# YT9215 register map
Vendor: Motorcomm; Series: YT921x; File version: 1.0
Registers are 32-bit, read-write, no defined reset value unless marked. A register's access mark holds for its fields unless they carry their own. Offsets are from the block's base; [hi:lo] are bit positions; lines under a group give offsets from that group; {n}, {i} and the like mark numbered series; 'fields as' and 'values as' point back to an identical list.

## EDATA — Configuration byte store and clock
Base 0x000E0000
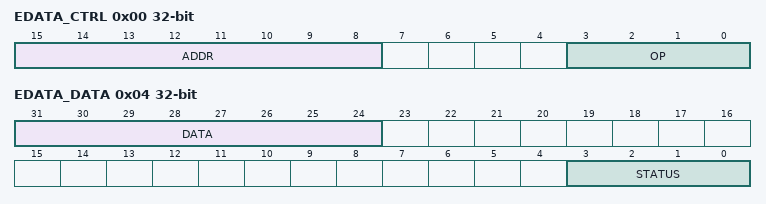
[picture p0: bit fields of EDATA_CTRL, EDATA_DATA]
0x00 EDATA_CTRL — Command register of the configuration byte store of 256 bytes. Writing it starts the command; Identify the part shows the read sequence.
  [15:8] ADDR — Byte address from 0 to 255.
  [3:0] OP — Command.
    5=READ (Read the byte at EDATA_CTRL.ADDR into EDATA_DATA.DATA)
0x04 EDATA_DATA ro — Result and state of the last EDATA_CTRL command.
  [31:24] DATA — Byte that was read.
  [3:0] STATUS — State of the store.
    3=IDLE (No command is running. EDATA_DATA.DATA is valid)
0x40 SYS_CLK — Shows which core clock the switch runs from. yt921x_chip_detect reads it. The time slots of METER_SLOT and PORT_SHAPE_SLOT count in units of eight core clock periods.
  [1:0] SEL — Core clock in use. Value 0 stands for 125 MHz in the YT9215 family and 167 MHz in the YT9218 family. The core clock table lists the clock periods.
    0=V125M (125 MHz core clock); 1=V143M (143 MHz core clock)

## INT_MBUS — Internal MDIO master
Base 0x000F0000
0x00 INT_MBUS_OP — Starts a transfer on the internal MDIO master and shows when it has finished; see MDIO master transfer.
  [0] START — Write 1 to start the transfer set up in INT_MBUS_CTRL. Reads 1 until the transfer is complete.
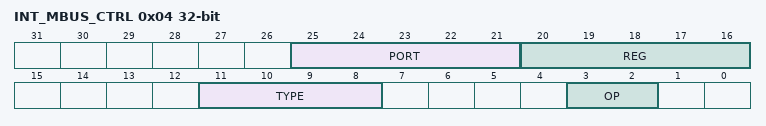
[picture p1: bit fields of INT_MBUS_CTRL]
0x04 INT_MBUS_CTRL — Address and direction of the next transfer to a built-in PHY or SerDes PCS.
  [25:21] PORT — PHY address from 0 to 31. On the internal bus it equals the port number.
  [20:16] REG — PHY register number from 0 to 31.
  [11:8] TYPE — Frame format. The comment on the field reads "wild guess", so the width of the field is inferred.
    4=C22 (IEEE 802.3 clause 22 frame)
  [3:2] OP — Direction. The comment on the field reads "wild guess", so the width of the field is inferred.
    1=WRITE (Write the register); 2=READ (Read the register)
0x08 INT_MBUS_DOUT — Data for the next write transfer on the internal MDIO master.
  [15:0] DATA — The 16-bit PHY register value.
0x0C INT_MBUS_DIN ro — Data returned by the last read transfer on the internal MDIO master.
  [15:0] DATA — The 16-bit PHY register value.

## EGRESS — Egress tag processing
Base 0x00100000
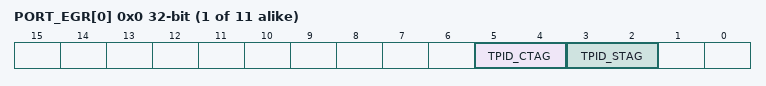
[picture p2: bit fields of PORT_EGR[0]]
{0x0+4i} PORT_EGR[{i}] (i=0..10) — Chooses which TPID_EGR entry a port writes into the VLAN tags it adds on transmit. Index: port = 0 to 10.
  [5:4] TPID_CTAG — Index of the TPID_EGR entry used for customer tags.
  [3:2] TPID_STAG — Index of the TPID_EGR entry used for service tags.
{0x300+4i} TPID_EGR[{i}] (i=0..3) — Four tag protocol identifier values a port can write into transmitted VLAN tags. Index: n = 0 to 3.
  [15:0] TPID — Tag protocol identifier. An example is 0x8100.

## ACL_ACTION — ACL action table
Base 0x001C0000
{0x0+0x10*i} ACL_ACT[{i}] (i=0..383) group — 96-bit action of one rule. The entry index is 8 × blk + the group number of the rule in ACL_ENTRY.GRPID. Write the three words in rising address order. Index: entry = 0 to 383.
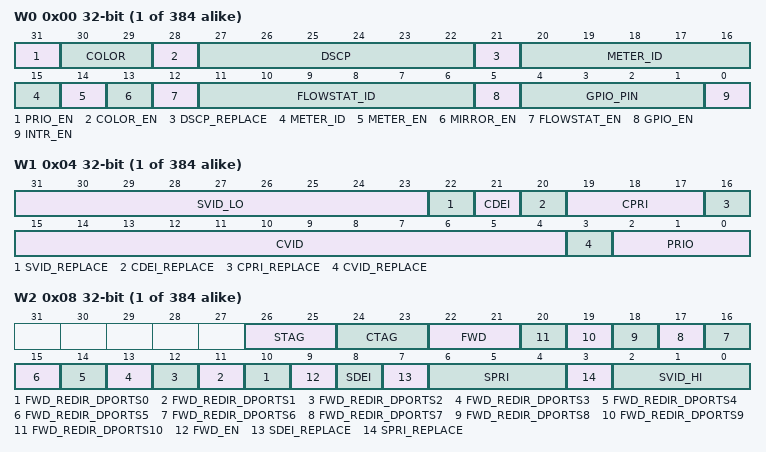
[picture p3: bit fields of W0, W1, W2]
  0x00 W0 — ACL action entry: bits 31 to 0. 96-bit action of one rule. The entry index is 8 × blk + the group number of the rule in ACL_ENTRY.GRPID. Write the three words in rising address order.
    [31] PRIO_EN — Enables ACL_ACT.PRIO.
    [30:29] COLOR — Colour given to the frame.
      0=GREEN; 1=YELLOW; 2=RED
    [28] COLOR_EN — Enables ACL_ACT.COLOR.
    [27:22] DSCP — New IP DSCP value.
    [21] DSCP_REPLACE — Replace the IP DSCP value.
    [20:15] METER_ID — Meter that rate limits matching frames. It is an index of METER_CTRL.
    [14] METER_EN — Enables ACL_ACT.METER_ID.
    [13] MIRROR_EN — Copy matching frames to the monitor port in MIRROR.PORT.
    [12] FLOWSTAT_EN — Count matching frames in the flow counter ACL_ACT.FLOWSTAT_ID.
    [11:6] FLOWSTAT_ID — Flow counter number.
    [5] GPIO_EN — Signal a match on the pin in ACL_ACT.GPIO_PIN.
    [4:1] GPIO_PIN — Pin number.
    [0] INTR_EN — Raise an interrupt on a match.
  0x04 W1 — ACL action entry: bits 63 to 32. 96-bit action of one rule. The entry index is 8 × blk + the group number of the rule in ACL_ENTRY.GRPID. Write the three words in rising address order.
    [31:23] SVID_LO — New service VLAN ID. The field crosses the boundary between words 1 and 2.
    [22] SVID_REPLACE — Replace the service VLAN ID.
    [21] CDEI — New drop eligible bit of the customer tag.
    [20] CDEI_REPLACE — Replace the drop eligible bit of the customer tag.
    [19:17] CPRI — New priority of the customer tag.
    [16] CPRI_REPLACE — Replace the priority of the customer tag.
    [15:4] CVID — New customer VLAN ID.
    [3] CVID_REPLACE — Replace the customer VLAN ID.
    [2:0] PRIO — Internal priority given to the frame. It is inferred that it is a source for PORT_PRIO_ORD.
  0x08 W2 — ACL action entry: bits 95 to 64. 96-bit action of one rule. The entry index is 8 × blk + the group number of the rule in ACL_ENTRY.GRPID. Write the three words in rising address order.
    [26:25] STAG — Service tag handling on transmit.
      0=DONTCARE (Leave to the normal VLAN rules); 1=UNTAG (Send without the tag); 2=TAG (Send with the tag); 3=KEEP (Send as received)
    [24:23] CTAG — Customer tag handling on transmit.
      values as STAG
    [22:21] FWD — Forwarding action. It is used when ACL_ACT.FWD_EN is set.
      0=FWD (Forward normally); 1=COPY (Forward and also send to ACL_ACT.FWD_REDIR_DPORTS); 2=REDIR (Send only to ACL_ACT.FWD_REDIR_DPORTS); 3=TRAP (Send only to the CPU)
    [n+10] FWD_REDIR_DPORTS{n} (n=0..10) — Destination ports for ACL_ACT.FWD.COPY and ACL_ACT.FWD.REDIR. Each port has one bit. ACL_ACT.FWD.REDIR with no port set drops the frame.
    [9] FWD_EN — Enables the forwarding action.
    [8] SDEI — New drop eligible bit of the service tag.
    [7] SDEI_REPLACE — Replace the drop eligible bit of the service tag.
    [6:4] SPRI — New priority of the service tag.
    [3] SPRI_REPLACE — Replace the priority of the service tag.
    [2:0] SVID_HI — New service VLAN ID. The field crosses the boundary between words 1 and 2.
